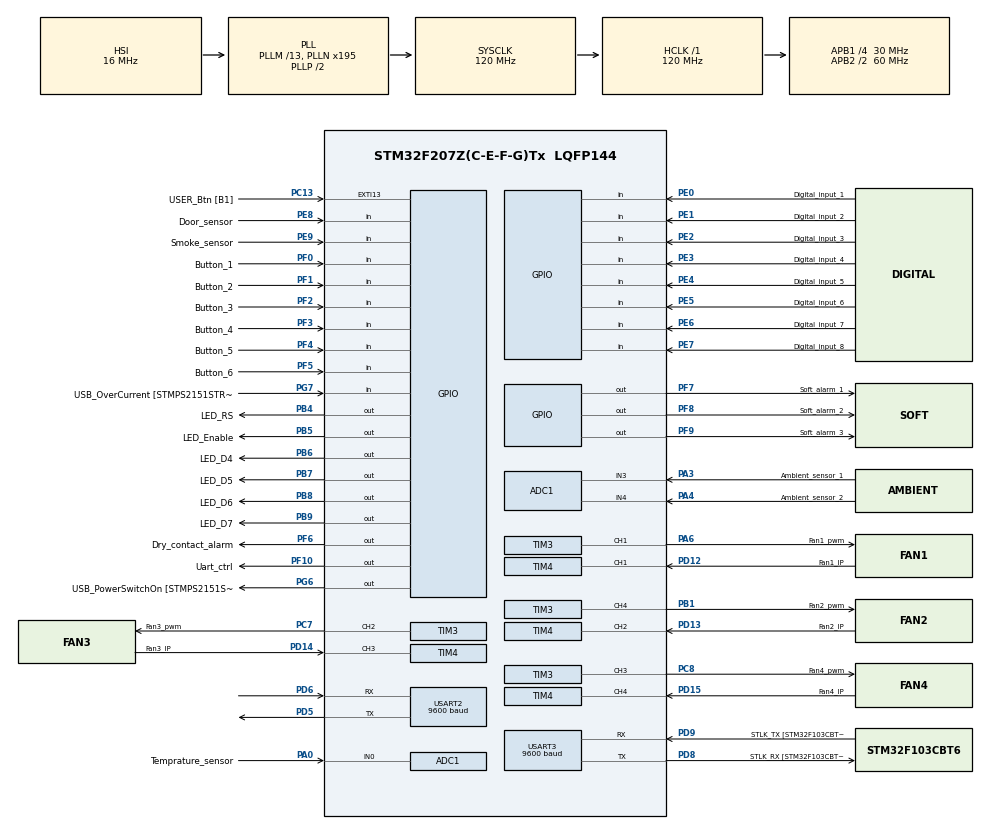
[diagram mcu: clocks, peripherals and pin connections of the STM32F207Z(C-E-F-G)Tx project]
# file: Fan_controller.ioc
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ADC1.Channel-0\#ChannelRegularConversion=ADC_CHANNEL_0
ADC1.Channel-1\#ChannelRegularConversion=ADC_CHANNEL_3
ADC1.Channel-2\#ChannelRegularConversion=ADC_CHANNEL_4
ADC1.ContinuousConvMode=ENABLE
ADC1.NbrOfConversion=3
ADC1.NbrOfConversionFlag=1
ADC1.Rank-0\#ChannelRegularConversion=1
ADC1.Rank-1\#ChannelRegularConversion=2
ADC1.Rank-2\#ChannelRegularConversion=3
ADC1.SamplingTime-0\#ChannelRegularConversion=ADC_SAMPLETIME_480CYCLES
ADC1.SamplingTime-1\#ChannelRegularConversion=ADC_SAMPLETIME_480CYCLES
ADC1.SamplingTime-2\#ChannelRegularConversion=ADC_SAMPLETIME_480CYCLES
ADC1.master=1
Mcu.Family=STM32F2
Mcu.Name=STM32F207Z(C-E-F-G)Tx
Mcu.Package=LQFP144
NVIC.ADC_IRQn=true\:0\:0\:false\:false\:true\:true\:true\:true
NVIC.PriorityGroup=NVIC_PRIORITYGROUP_4
NVIC.TIM3_IRQn=true\:0\:0\:false\:false\:true\:true\:true\:true
NVIC.TIM4_IRQn=true\:0\:0\:false\:false\:true\:true\:true\:true
NVIC.TIM6_DAC_IRQn=true\:0\:0\:false\:false\:true\:true\:true\:true
NVIC.USART2_IRQn=true\:0\:0\:false\:false\:true\:true\:true\:true
NVIC.USART3_IRQn=true\:0\:0\:false\:false\:true\:true\:true\:true
PA0-WKUP.GPIO_Label=Temprature_sensor
PA0-WKUP.Signal=ADCx_IN0
PA1.GPIO_Label=RMII_REF_CLK [LAN8742A-CZ-TR_REFCLK0]
PA1.Signal=ETH_REF_CLK
PA10.GPIO_Label=USB_ID
PA10.Signal=USB_OTG_FS_ID
PA11.GPIO_Label=USB_DM
PA11.Signal=USB_OTG_FS_DM
PA12.GPIO_Label=USB_DP
PA12.Signal=USB_OTG_FS_DP
PA13.GPIO_Label=TMS
PA13.Mode=Serial_Wire
PA13.Signal=SYS_JTMS-SWDIO
PA14.GPIO_Label=TCK
PA14.Mode=Serial_Wire
PA14.Signal=SYS_JTCK-SWCLK
PA2.GPIO_Label=RMII_MDIO [LAN8742A-CZ-TR_MDIO]
PA2.Signal=ETH_MDIO
PA3.GPIO_Label=Ambient_sensor_1
PA3.Signal=ADCx_IN3
PA4.GPIO_Label=Ambient_sensor_2
PA4.Signal=ADCx_IN4
PA6.GPIO_Label=Fan1_pwm
PA6.Signal=S_TIM3_CH1
PA7.GPIO_Label=RMII_CRS_DV [LAN8742A-CZ-TR_CRS_DV]
PA7.Signal=ETH_CRS_DV
PA8.GPIO_Label=USB_SOF [TP1]
PA8.Signal=USB_OTG_FS_SOF
PA9.GPIO_Label=USB_VBUS
PA9.Signal=USB_OTG_FS_VBUS
PB1.GPIO_Label=Fan2_pwm
PB1.Signal=S_TIM3_CH4
PB13.GPIO_Label=RMII_TXD1 [LAN8742A-CZ-TR_TXD1]
PB13.Signal=ETH_TXD1
PB3.GPIO_Label=SWO
PB3.Signal=SYS_JTDO-SWO
PB4.GPIO_Label=LED_RS
PB4.Signal=GPIO_Output
PB5.GPIO_Label=LED_Enable
PB5.Signal=GPIO_Output
PB6.GPIO_Label=LED_D4
PB6.Signal=GPIO_Output
PB7.GPIO_Label=LED_D5
PB7.Signal=GPIO_Output
PB8.GPIO_Label=LED_D6
PB8.Signal=GPIO_Output
PB9.GPIO_Label=LED_D7
PB9.Signal=GPIO_Output
PC1.GPIO_Label=RMII_MDC [LAN8742A-CZ-TR_MDC]
PC1.Signal=ETH_MDC
PC13.GPIO_Label=USER_Btn [B1]
PC13.Signal=GPXTI13
PC14-OSC32_IN.Signal=RCC_OSC32_IN
PC15-OSC32_OUT.Signal=RCC_OSC32_OUT
PC4.GPIO_Label=RMII_RXD0 [LAN8742A-CZ-TR_RXD0]
PC4.Signal=ETH_RXD0
PC5.GPIO_Label=RMII_RXD1 [LAN8742A-CZ-TR_RXD1]
PC5.Signal=ETH_RXD1
PC7.GPIO_Label=Fan3_pwm
PC7.Signal=S_TIM3_CH2
PC8.GPIO_Label=Fan4_pwm
PC8.Signal=S_TIM3_CH3
PD12.GPIO_Label=Fan1_IP
PD12.Signal=S_TIM4_CH1
PD13.GPIO_Label=Fan2_IP
PD13.Signal=S_TIM4_CH2
PD14.GPIO_Label=Fan3_IP
PD14.Signal=S_TIM4_CH3
PD15.GPIO_Label=Fan4_IP
PD15.Signal=S_TIM4_CH4
PD5.Mode=Asynchronous
PD5.Signal=USART2_TX
PD6.Mode=Asynchronous
PD6.Signal=USART2_RX
PD8.GPIO_Label=STLK_RX [STM32F103CBT6_PA2]
PD8.Mode=Asynchronous
PD8.Signal=USART3_TX
PD9.GPIO_Label=STLK_TX [STM32F103CBT6_PA3]
PD9.Mode=Asynchronous
PD9.Signal=USART3_RX
PE0.GPIO_Label=Digital_input_1
PE0.Signal=GPIO_Input
PE1.GPIO_Label=Digital_input_2
PE1.Signal=GPIO_Input
PE2.GPIO_Label=Digital_input_3
PE2.Signal=GPIO_Input
PE3.GPIO_Label=Digital_input_4
PE3.Signal=GPIO_Input
PE4.GPIO_Label=Digital_input_5
PE4.Signal=GPIO_Input
PE5.GPIO_Label=Digital_input_6
PE5.Signal=GPIO_Input
PE6.GPIO_Label=Digital_input_7
PE6.Signal=GPIO_Input
PE7.GPIO_Label=Digital_input_8
PE7.Signal=GPIO_Input
PE8.GPIO_Label=Door_sensor
PE8.Signal=GPIO_Input
PE9.GPIO_Label=Smoke_sensor
PE9.Signal=GPIO_Input
PF0.GPIO_Label=Button_1
PF0.Signal=GPIO_Input
PF1.GPIO_Label=Button_2
PF1.Signal=GPIO_Input
PF10.GPIO_Label=Uart_ctrl
PF10.Signal=GPIO_Output
PF2.GPIO_Label=Button_3
PF2.Signal=GPIO_Input
PF3.GPIO_Label=Button_4
PF3.Signal=GPIO_Input
PF4.GPIO_Label=Button_5
PF4.Signal=GPIO_Input
PF5.GPIO_Label=Button_6
PF5.Signal=GPIO_Input
PF6.GPIO_Label=Dry_contact_alarm
PF6.Signal=GPIO_Output
PF7.GPIO_Label=Soft_alarm_1
PF7.Signal=GPIO_Output
PF8.GPIO_Label=Soft_alarm_2
PF8.Signal=GPIO_Output
PF9.GPIO_Label=Soft_alarm_3
PF9.Signal=GPIO_Output
PG11.GPIO_Label=RMII_TX_EN [LAN8742A-CZ-TR_TXEN]
PG11.Signal=ETH_TX_EN
PG13.GPIO_Label=RMII_TXD0 [LAN8742A-CZ-TR_TXD0]
PG13.Signal=ETH_TXD0
PG6.GPIO_Label=USB_PowerSwitchOn [STMPS2151STR_EN]
PG6.Signal=GPIO_Output
PG7.GPIO_Label=USB_OverCurrent [STMPS2151STR_FAULT]
PG7.Signal=GPIO_Input
PH0-OSC_IN.GPIO_Label=MCO [STM32F103CBT6_PA8]
PH0-OSC_IN.Mode=HSE-External-Oscillator
PH0-OSC_IN.Signal=RCC_OSC_IN
PH1-OSC_OUT.Mode=HSE-External-Oscillator
PH1-OSC_OUT.Signal=RCC_OSC_OUT
ProjectManager.HeapSize=0x200
ProjectManager.StackSize=0x400
ProjectManager.TargetToolchain=STM32CubeIDE
RCC.48MHZClocksFreq_Value=48000000
RCC.AHBFreq_Value=120000000
RCC.APB1CLKDivider=RCC_HCLK_DIV4
RCC.APB1Freq_Value=30000000
RCC.APB1TimFreq_Value=60000000
RCC.APB2CLKDivider=RCC_HCLK_DIV2
RCC.APB2Freq_Value=60000000
RCC.APB2TimFreq_Value=120000000
RCC.CortexFreq_Value=120000000
RCC.HCLKFreq_Value=120000000
RCC.HSE_VALUE=8000000
RCC.HSI_VALUE=16000000
RCC.LSE_VALUE=32768
RCC.PLLM=13
RCC.PLLMUL=RCC_PLL_MUL9
RCC.PLLN=195
RCC.PLLQ=5
RCC.PRESCALERUSB=RCC_USBCLKSOURCE_PLL_DIV1_5
RCC.SYSCLKFreq_VALUE=120000000
RCC.SYSCLKSource=RCC_SYSCLKSOURCE_PLLCLK
RCC.SYSCLKSourceVirtual=RCC_SYSCLKSOURCE_PLLCLK
RCC.USBFreq_Value=48000000
RCC.VCOOutputFreq_Value=240000000
SH.ADCx_IN0.0=ADC1_IN0,IN0
SH.ADCx_IN3.0=ADC1_IN3,IN3
SH.ADCx_IN4.0=ADC1_IN4,IN4
SH.S_TIM3_CH1.0=TIM3_CH1,PWM Generation1 CH1
SH.S_TIM3_CH2.0=TIM3_CH2,PWM Generation2 CH2
SH.S_TIM3_CH3.0=TIM3_CH3,PWM Generation3 CH3
SH.S_TIM3_CH4.0=TIM3_CH4,PWM Generation4 CH4
SH.S_TIM4_CH1.0=TIM4_CH1,Input_Capture1_from_TI1
SH.S_TIM4_CH2.0=TIM4_CH2,Input_Capture2_from_TI2
SH.S_TIM4_CH3.0=TIM4_CH3,Input_Capture3_from_TI3
SH.S_TIM4_CH4.0=TIM4_CH4,Input_Capture4_from_TI4
TIM3.AutoReloadPreload=TIM_AUTORELOAD_PRELOAD_ENABLE
TIM3.Channel-PWM\ Generation1\ CH1=TIM_CHANNEL_1
TIM3.Channel-PWM\ Generation2\ CH2=TIM_CHANNEL_2
TIM3.Channel-PWM\ Generation3\ CH3=TIM_CHANNEL_3
TIM3.Channel-PWM\ Generation4\ CH4=TIM_CHANNEL_4
TIM3.Period=100
TIM3.Prescaler=23
TIM4.Channel-Input_Capture1_from_TI1=TIM_CHANNEL_1
TIM4.Channel-Input_Capture2_from_TI2=TIM_CHANNEL_2
TIM4.Channel-Input_Capture3_from_TI3=TIM_CHANNEL_3
TIM4.Channel-Input_Capture4_from_TI4=TIM_CHANNEL_4
TIM6.AutoReloadPreload=TIM_AUTORELOAD_PRELOAD_ENABLE
TIM6.Period=2000
TIM6.Prescaler=600
USART2.BaudRate=9600
USART2.VirtualMode=VM_ASYNC
USART3.BaudRate=9600
USART3.VirtualMode=VM_ASYNC
VP_TIM3_VS_ClockSourceINT.Mode=Internal
VP_TIM4_VS_ClockSourceINT.Mode=Internal
VP_TIM6_VS_ClockSourceINT.Mode=Enable_Timer
board=NUCLEO-F207ZG

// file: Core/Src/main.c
/* USER CODE BEGIN Header */
/**
  ******************************************************************************
  * @file           : main.c
  * @brief          : Main program body
  ******************************************************************************
  * @attention
  *
  * Copyright (c) 2024 STMicroelectronics.
  * All rights reserved.
  *
  * This software is licensed under terms that can be found in the LICENSE file
  * in the root directory of this software component.
  * If no LICENSE file comes with this software, it is provided AS-IS.
  *
  ******************************************************************************
  */
/* USER CODE END Header */
#include "main.h"
#include "Fan.h"
#include <math.h>

void SystemClock_Config(void);
static void MX_GPIO_Init(void);
static void MX_USART3_UART_Init(void);
static void MX_ADC1_Init(void);
static void MX_TIM3_Init(void);
static void MX_TIM4_Init(void);
static void MX_USART2_UART_Init(void);
static void MX_TIM6_Init(void);
uint16_t Adc_buff[3];

int main(void)
{

  /* MCU Configuration--------------------------------------------------------*/

  /* Reset of all peripherals, Initializes the Flash interface and the Systick. */
  HAL_Init();

  /* Configure the system clock */
  SystemClock_Config();

  /* Initialize all configured peripherals */
  MX_GPIO_Init();
  MX_USART3_UART_Init();
  MX_ADC1_Init();
  MX_TIM3_Init();
  MX_TIM4_Init();
  MX_USART2_UART_Init();
  MX_TIM6_Init();

  /* USER CODE BEGIN 2 */
  HAL_TIM_Base_Start_IT(&htim6);
  HAL_ADC_Start_DMA(&hadc1, (uint32_t *) Adc_buff,3);
  /* USER CODE END 2 */

  /* Infinite loop */
  while (1)
  {

  }
}
void HAL_ADC_ConvCpltCallback(ADC_HandleTypeDef* hadc)
{
	Adc_Complition_flag = 1;
	Set_Fan_speed();
}

void HAL_TIM_PeriodElapsedCallback(TIM_HandleTypeDef *htim)
{
	if (htim->Instance == TIM6)
	{

		Read_sensors();
		Read_ADC_value();
		set_alarm();

	}

}

void Read_ADC_value()
{
	 if(Adc_Complition_flag)
		  {
			  for(uint8_t i=0; i<hadc1.Init.NbrOfConversion; i++)
			  {
				  Temperature_sensor = (uint16_t) Adc_buff[0]; // set temperature value as per sensor o/p in degree celcius
				  Ambient_sensor_1 = (uint16_t) Adc_buff[1];
				  Ambient_sensor_2 = (uint16_t) Adc_buff[2];
				  Adc_Complition_flag = 0;
				  HAL_ADC_Start_DMA(&hadc1, (uint32_t *) Adc_buff,3);

			  }
		  }
}

void Read_sensors()
{
	Door_status 	= (HAL_GPIO_ReadPin(Door_sensor_GPIO_Port, Door_sensor_Pin) == GPIO_PIN_SET) ? 1 : 0;
	Smoke_sensor 	= (HAL_GPIO_ReadPin(Smoke_sensor_GPIO_Port, Smoke_sensor_Pin) == GPIO_PIN_SET) ? 1 : 0;
	Digital_input_1 = (HAL_GPIO_ReadPin(Digital_input_1_GPIO_Port, Digital_input_1_Pin) == GPIO_PIN_SET) ? 1 : 0;
	Digital_input_2 = (HAL_GPIO_ReadPin(Digital_input_2_GPIO_Port, Digital_input_2_Pin) == GPIO_PIN_SET) ? 1 : 0;
	Digital_input_3 = (HAL_GPIO_ReadPin(Digital_input_3_GPIO_Port, Digital_input_3_Pin) == GPIO_PIN_SET) ? 1 : 0;
	Digital_input_4 = (HAL_GPIO_ReadPin(Digital_input_4_GPIO_Port, Digital_input_4_Pin) == GPIO_PIN_SET) ? 1 : 0;
	Digital_input_5 = (HAL_GPIO_ReadPin(Digital_input_5_GPIO_Port, Digital_input_5_Pin) == GPIO_PIN_SET) ? 1 : 0;
	Digital_input_6 = (HAL_GPIO_ReadPin(Digital_input_6_GPIO_Port, Digital_input_6_Pin) == GPIO_PIN_SET) ? 1 : 0;
	Digital_input_7 = (HAL_GPIO_ReadPin(Digital_input_7_GPIO_Port, Digital_input_7_Pin) == GPIO_PIN_SET) ? 1 : 0;
	Digital_input_8 = (HAL_GPIO_ReadPin(Digital_input_8_GPIO_Port, Digital_input_8_Pin) == GPIO_PIN_SET) ? 1 : 0;
}

void Set_Fan_speed()
{
	 float deltaT = fabs(Temperature_sensor - Ambient_sensor_1); // Make delta positive
	 uint8_t duty_cycle = 0;

	 	 if (Temperature_sensor < 30)
	 	 {
	         duty_cycle = 0; // Off
	     }
	     else if (Temperature_sensor < 35)
	     {
	         duty_cycle = 20;
	     }
	     else if (Temperature_sensor < 40)
	     {
	         if (deltaT <= 2.5)
	         {
	             duty_cycle = 20;         // Delta T <= 2.5
	         }
	         else if (deltaT <= 5.0)
	         {
	             duty_cycle = 30;         // 2.5 < Delta T <= 5.0
	         }
	         else if (deltaT <= 7.5)
	         {
	             duty_cycle = 40;         // 5.0 < Delta T <= 7.5
	         }
	         else if (deltaT <= 10)
	         {
	             duty_cycle = 50;         // 7.5 < Delta T <= 10
	         }
	         else if (deltaT <= 12.5)
	         {
	             duty_cycle = 60;         // 10 < Delta T <= 12.5
	         }
	         else
	         {
	             duty_cycle = 80;         // Delta T > 12.5
	         }
	     }
	     else if (Temperature_sensor < 45)
	     {
	         if (deltaT <= 2.5)
	         {
	             duty_cycle = 30;         // Delta T <= 2.5
	         }
	         else if (deltaT <= 5.0)
	         {
	             duty_cycle = 40;         // 2.5 < Delta T <= 5.0
	         }
	         else if (deltaT <= 7.5)
	         {
	             duty_cycle = 70;         // 5.0 < Delta T <= 7.5
	         }
	         else if (deltaT <= 10)
	         {
	             duty_cycle = 80;         // 7.5 < Delta T <= 10
	         }
	         else if (deltaT <= 12.5)
	         {
	             duty_cycle = 90;         // 10 < Delta T <= 12.5
	         }
	         else
	         {
	             duty_cycle = 100;        // Delta T > 12.5
	         }
	     }
	     else if (Temperature_sensor < 50)
	     {
	         if (deltaT <= 2.5)

	         {
	             duty_cycle = 50;         // Delta T <= 2.5
	         }
	         else if (deltaT <= 5.0)
	         {
	             duty_cycle = 80;         // 2.5 < Delta T <= 5.0
	         }
	         else
	         {
	             duty_cycle = 100;        // Delta T > 5.0
	         }
	     }
	     else
	     {
	         if (deltaT < 2.5)
	         {
	             duty_cycle = 70;         // Delta T < 2.5
	         }
	         else
	         {
	             duty_cycle = 100;        // Delta T >= 2.5
	         }
	     }
	 	__HAL_TIM_SET_COMPARE(&htim3, TIM_CHANNEL_1, duty_cycle);
	 	__HAL_TIM_SET_COMPARE(&htim3, TIM_CHANNEL_2, duty_cycle);
	 	__HAL_TIM_SET_COMPARE(&htim3, TIM_CHANNEL_3, duty_cycle);
	 	__HAL_TIM_SET_COMPARE(&htim3, TIM_CHANNEL_4, duty_cycle);
}

void SystemClock_Config(void)
{
  RCC_OscInitTypeDef RCC_OscInitStruct = {0};
  RCC_ClkInitTypeDef RCC_ClkInitStruct = {0};

  /** Initializes the RCC Oscillators according to the specified parameters
  * in the RCC_OscInitTypeDef structure.
  */
  RCC_OscInitStruct.OscillatorType = RCC_OSCILLATORTYPE_HSI;
  RCC_OscInitStruct.HSIState = RCC_HSI_ON;
  RCC_OscInitStruct.HSICalibrationValue = RCC_HSICALIBRATION_DEFAULT;
  RCC_OscInitStruct.PLL.PLLState = RCC_PLL_ON;
  RCC_OscInitStruct.PLL.PLLSource = RCC_PLLSOURCE_HSI;
  RCC_OscInitStruct.PLL.PLLM = 13;
  RCC_OscInitStruct.PLL.PLLN = 195;
  RCC_OscInitStruct.PLL.PLLP = RCC_PLLP_DIV2;
  RCC_OscInitStruct.PLL.PLLQ = 5;
  if (HAL_RCC_OscConfig(&RCC_OscInitStruct) != HAL_OK)
  {
    Error_Handler();
  }

  /** Initializes the CPU, AHB and APB buses clocks
  */
  RCC_ClkInitStruct.ClockType = RCC_CLOCKTYPE_HCLK|RCC_CLOCKTYPE_SYSCLK
                              |RCC_CLOCKTYPE_PCLK1|RCC_CLOCKTYPE_PCLK2;
  RCC_ClkInitStruct.SYSCLKSource = RCC_SYSCLKSOURCE_PLLCLK;
  RCC_ClkInitStruct.AHBCLKDivider = RCC_SYSCLK_DIV1;
  RCC_ClkInitStruct.APB1CLKDivider = RCC_HCLK_DIV4;
  RCC_ClkInitStruct.APB2CLKDivider = RCC_HCLK_DIV2;

  if (HAL_RCC_ClockConfig(&RCC_ClkInitStruct, FLASH_LATENCY_3) != HAL_OK)
  {
    Error_Handler();
  }
}

static void MX_ADC1_Init(void)
{

  ADC_ChannelConfTypeDef sConfig = {0};

  /** Configure the global features of the ADC (Clock, Resolution, Data Alignment and number of conversion)
  */
  hadc1.Instance = ADC1;
  hadc1.Init.ClockPrescaler = ADC_CLOCK_SYNC_PCLK_DIV2;
  hadc1.Init.Resolution = ADC_RESOLUTION_12B;
  hadc1.Init.ScanConvMode = ENABLE;
  hadc1.Init.ContinuousConvMode = ENABLE;
  hadc1.Init.DiscontinuousConvMode = DISABLE;
  hadc1.Init.ExternalTrigConvEdge = ADC_EXTERNALTRIGCONVEDGE_NONE;
  hadc1.Init.ExternalTrigConv = ADC_SOFTWARE_START;
  hadc1.Init.DataAlign = ADC_DATAALIGN_RIGHT;
  hadc1.Init.NbrOfConversion = 3;
  hadc1.Init.DMAContinuousRequests = DISABLE;
  hadc1.Init.EOCSelection = ADC_EOC_SINGLE_CONV;
  if (HAL_ADC_Init(&hadc1) != HAL_OK)
  {
    Error_Handler();
  }

  /** Configure for the selected ADC regular channel its corresponding rank in the sequencer and its sample time.
  */
  sConfig.Channel = ADC_CHANNEL_0;
  sConfig.Rank = 1;
  sConfig.SamplingTime = ADC_SAMPLETIME_480CYCLES;
  if (HAL_ADC_ConfigChannel(&hadc1, &sConfig) != HAL_OK)
  {
    Error_Handler();
  }

  /** Configure for the selected ADC regular channel its corresponding rank in the sequencer and its sample time.
  */
  sConfig.Channel = ADC_CHANNEL_3;
  sConfig.Rank = 2;
  if (HAL_ADC_ConfigChannel(&hadc1, &sConfig) != HAL_OK)
  {
    Error_Handler();
  }

  /** Configure for the selected ADC regular channel its corresponding rank in the sequencer and its sample time.
  */
  sConfig.Channel = ADC_CHANNEL_4;
  sConfig.Rank = 3;
  if (HAL_ADC_ConfigChannel(&hadc1, &sConfig) != HAL_OK)
  {
    Error_Handler();
  }

}

static void MX_TIM3_Init(void)
{

  TIM_ClockConfigTypeDef sClockSourceConfig = {0};
  TIM_MasterConfigTypeDef sMasterConfig = {0};
  TIM_OC_InitTypeDef sConfigOC = {0};

  htim3.Instance = TIM3;
  htim3.Init.Prescaler = 23;
  htim3.Init.CounterMode = TIM_COUNTERMODE_UP;
  htim3.Init.Period = 100;
  htim3.Init.ClockDivision = TIM_CLOCKDIVISION_DIV1;
  htim3.Init.AutoReloadPreload = TIM_AUTORELOAD_PRELOAD_ENABLE;
  if (HAL_TIM_Base_Init(&htim3) != HAL_OK)
  {
    Error_Handler();
  }
  sClockSourceConfig.ClockSource = TIM_CLOCKSOURCE_INTERNAL;
  if (HAL_TIM_ConfigClockSource(&htim3, &sClockSourceConfig) != HAL_OK)
  {
    Error_Handler();
  }
  if (HAL_TIM_PWM_Init(&htim3) != HAL_OK)
  {
    Error_Handler();
  }
  sMasterConfig.MasterOutputTrigger = TIM_TRGO_RESET;
  sMasterConfig.MasterSlaveMode = TIM_MASTERSLAVEMODE_DISABLE;
  if (HAL_TIMEx_MasterConfigSynchronization(&htim3, &sMasterConfig) != HAL_OK)
  {
    Error_Handler();
  }
  sConfigOC.OCMode = TIM_OCMODE_PWM1;
  sConfigOC.Pulse = 0;
  sConfigOC.OCPolarity = TIM_OCPOLARITY_HIGH;
  sConfigOC.OCFastMode = TIM_OCFAST_DISABLE;
  if (HAL_TIM_PWM_ConfigChannel(&htim3, &sConfigOC, TIM_CHANNEL_1) != HAL_OK)
  {
    Error_Handler();
  }
  if (HAL_TIM_PWM_ConfigChannel(&htim3, &sConfigOC, TIM_CHANNEL_2) != HAL_OK)
  {
    Error_Handler();
  }
  if (HAL_TIM_PWM_ConfigChannel(&htim3, &sConfigOC, TIM_CHANNEL_3) != HAL_OK)
  {
    Error_Handler();
  }
  if (HAL_TIM_PWM_ConfigChannel(&htim3, &sConfigOC, TIM_CHANNEL_4) != HAL_OK)
  {
    Error_Handler();
  }
  HAL_TIM_MspPostInit(&htim3);

}

static void MX_TIM4_Init(void)
{

  TIM_ClockConfigTypeDef sClockSourceConfig = {0};
  TIM_MasterConfigTypeDef sMasterConfig = {0};
  TIM_IC_InitTypeDef sConfigIC = {0};

  htim4.Instance = TIM4;
  htim4.Init.Prescaler = 0;
  htim4.Init.CounterMode = TIM_COUNTERMODE_UP;
  htim4.Init.Period = 65535;
  htim4.Init.ClockDivision = TIM_CLOCKDIVISION_DIV1;
  htim4.Init.AutoReloadPreload = TIM_AUTORELOAD_PRELOAD_DISABLE;
  if (HAL_TIM_Base_Init(&htim4) != HAL_OK)
  {
    Error_Handler();
  }
  sClockSourceConfig.ClockSource = TIM_CLOCKSOURCE_INTERNAL;
  if (HAL_TIM_ConfigClockSource(&htim4, &sClockSourceConfig) != HAL_OK)
  {
    Error_Handler();
  }
  if (HAL_TIM_IC_Init(&htim4) != HAL_OK)
  {
    Error_Handler();
  }
  sMasterConfig.MasterOutputTrigger = TIM_TRGO_RESET;
  sMasterConfig.MasterSlaveMode = TIM_MASTERSLAVEMODE_DISABLE;
  if (HAL_TIMEx_MasterConfigSynchronization(&htim4, &sMasterConfig) != HAL_OK)
  {
    Error_Handler();
  }
  sConfigIC.ICPolarity = TIM_INPUTCHANNELPOLARITY_RISING;
  sConfigIC.ICSelection = TIM_ICSELECTION_DIRECTTI;
  sConfigIC.ICPrescaler = TIM_ICPSC_DIV1;
  sConfigIC.ICFilter = 0;
  if (HAL_TIM_IC_ConfigChannel(&htim4, &sConfigIC, TIM_CHANNEL_1) != HAL_OK)
  {
    Error_Handler();
  }
  if (HAL_TIM_IC_ConfigChannel(&htim4, &sConfigIC, TIM_CHANNEL_2) != HAL_OK)
  {
    Error_Handler();
  }
  if (HAL_TIM_IC_ConfigChannel(&htim4, &sConfigIC, TIM_CHANNEL_3) != HAL_OK)
  {
    Error_Handler();
  }
  if (HAL_TIM_IC_ConfigChannel(&htim4, &sConfigIC, TIM_CHANNEL_4) != HAL_OK)
  {
    Error_Handler();
  }

}

static void MX_TIM6_Init(void)
{

  TIM_MasterConfigTypeDef sMasterConfig = {0};

  htim6.Instance = TIM6;
  htim6.Init.Prescaler = 600;
  htim6.Init.CounterMode = TIM_COUNTERMODE_UP;
  htim6.Init.Period = 2000;
  htim6.Init.AutoReloadPreload = TIM_AUTORELOAD_PRELOAD_ENABLE;
  if (HAL_TIM_Base_Init(&htim6) != HAL_OK)
  {
    Error_Handler();
  }
  sMasterConfig.MasterOutputTrigger = TIM_TRGO_RESET;
  sMasterConfig.MasterSlaveMode = TIM_MASTERSLAVEMODE_DISABLE;
  if (HAL_TIMEx_MasterConfigSynchronization(&htim6, &sMasterConfig) != HAL_OK)
  {
    Error_Handler();
  }

}

static void MX_USART2_UART_Init(void)
{

  huart2.Instance = USART2;
  huart2.Init.BaudRate = 9600;
  huart2.Init.WordLength = UART_WORDLENGTH_8B;
  huart2.Init.StopBits = UART_STOPBITS_1;
  huart2.Init.Parity = UART_PARITY_NONE;
  huart2.Init.Mode = UART_MODE_TX_RX;
  huart2.Init.HwFlowCtl = UART_HWCONTROL_NONE;
  huart2.Init.OverSampling = UART_OVERSAMPLING_16;
  if (HAL_UART_Init(&huart2) != HAL_OK)
  {
    Error_Handler();
  }

}

static void MX_USART3_UART_Init(void)
{

  huart3.Instance = USART3;
  huart3.Init.BaudRate = 9600;
  huart3.Init.WordLength = UART_WORDLENGTH_8B;
  huart3.Init.StopBits = UART_STOPBITS_1;
  huart3.Init.Parity = UART_PARITY_NONE;
  huart3.Init.Mode = UART_MODE_TX_RX;
  huart3.Init.HwFlowCtl = UART_HWCONTROL_NONE;
  huart3.Init.OverSampling = UART_OVERSAMPLING_16;
  if (HAL_UART_Init(&huart3) != HAL_OK)
  {
    Error_Handler();
  }

}

static void MX_GPIO_Init(void)
{
  GPIO_InitTypeDef GPIO_InitStruct = {0};

  /* GPIO Ports Clock Enable */
  __HAL_RCC_GPIOE_CLK_ENABLE();
  __HAL_RCC_GPIOC_CLK_ENABLE();
  __HAL_RCC_GPIOF_CLK_ENABLE();
  __HAL_RCC_GPIOH_CLK_ENABLE();
  __HAL_RCC_GPIOA_CLK_ENABLE();
  __HAL_RCC_GPIOB_CLK_ENABLE();
  __HAL_RCC_GPIOD_CLK_ENABLE();
  __HAL_RCC_GPIOG_CLK_ENABLE();

  /*Configure GPIO pin Output Level */
  HAL_GPIO_WritePin(GPIOF, Dry_contact_alarm_Pin|Soft_alarm_1_Pin|Soft_alarm_2_Pin|Soft_alarm_3_Pin
                          |Uart_ctrl_Pin, GPIO_PIN_RESET);

  /*Configure GPIO pin Output Level */
  HAL_GPIO_WritePin(USB_PowerSwitchOn_GPIO_Port, USB_PowerSwitchOn_Pin, GPIO_PIN_RESET);

  /*Configure GPIO pin Output Level */
  HAL_GPIO_WritePin(GPIOB, LED_RS_Pin|LED_Enable_Pin|LED_D4_Pin|LED_D5_Pin
                          |LED_D6_Pin|LED_D7_Pin, GPIO_PIN_RESET);

  /*Configure GPIO pins : Digital_input_3_Pin Digital_input_4_Pin Digital_input_5_Pin Digital_input_6_Pin
                           Digital_input_7_Pin Digital_input_8_Pin Door_sensor_Pin Smoke_sensor_Pin
                           Digital_input_1_Pin Digital_input_2_Pin */
  GPIO_InitStruct.Pin = Digital_input_3_Pin|Digital_input_4_Pin|Digital_input_5_Pin|Digital_input_6_Pin
                          |Digital_input_7_Pin|Digital_input_8_Pin|Door_sensor_Pin|Smoke_sensor_Pin
                          |Digital_input_1_Pin|Digital_input_2_Pin;
  GPIO_InitStruct.Mode = GPIO_MODE_INPUT;
  GPIO_InitStruct.Pull = GPIO_NOPULL;
  HAL_GPIO_Init(GPIOE, &GPIO_InitStruct);

  /*Configure GPIO pin : USER_Btn_Pin */
  GPIO_InitStruct.Pin = USER_Btn_Pin;
  GPIO_InitStruct.Mode = GPIO_MODE_IT_RISING;
  GPIO_InitStruct.Pull = GPIO_NOPULL;
  HAL_GPIO_Init(USER_Btn_GPIO_Port, &GPIO_InitStruct);

  /*Configure GPIO pins : Button_1_Pin Button_2_Pin Button_3_Pin Button_4_Pin
                           Button_5_Pin Button_6_Pin */
  GPIO_InitStruct.Pin = Button_1_Pin|Button_2_Pin|Button_3_Pin|Button_4_Pin
                          |Button_5_Pin|Button_6_Pin;
  GPIO_InitStruct.Mode = GPIO_MODE_INPUT;
  GPIO_InitStruct.Pull = GPIO_NOPULL;
  HAL_GPIO_Init(GPIOF, &GPIO_InitStruct);

  /*Configure GPIO pins : Dry_contact_alarm_Pin Soft_alarm_1_Pin Soft_alarm_2_Pin Soft_alarm_3_Pin
                           Uart_ctrl_Pin */
  GPIO_InitStruct.Pin = Dry_contact_alarm_Pin|Soft_alarm_1_Pin|Soft_alarm_2_Pin|Soft_alarm_3_Pin
                          |Uart_ctrl_Pin;
  GPIO_InitStruct.Mode = GPIO_MODE_OUTPUT_PP;
  GPIO_InitStruct.Pull = GPIO_NOPULL;
  GPIO_InitStruct.Speed = GPIO_SPEED_FREQ_LOW;
  HAL_GPIO_Init(GPIOF, &GPIO_InitStruct);

  /*Configure GPIO pins : RMII_MDC_Pin RMII_RXD0_Pin RMII_RXD1_Pin */
  GPIO_InitStruct.Pin = RMII_MDC_Pin|RMII_RXD0_Pin|RMII_RXD1_Pin;
  GPIO_InitStruct.Mode = GPIO_MODE_AF_PP;
  GPIO_InitStruct.Pull = GPIO_NOPULL;
  GPIO_InitStruct.Speed = GPIO_SPEED_FREQ_VERY_HIGH;
  GPIO_InitStruct.Alternate = GPIO_AF11_ETH;
  HAL_GPIO_Init(GPIOC, &GPIO_InitStruct);

  /*Configure GPIO pins : RMII_REF_CLK_Pin RMII_MDIO_Pin RMII_CRS_DV_Pin */
  GPIO_InitStruct.Pin = RMII_REF_CLK_Pin|RMII_MDIO_Pin|RMII_CRS_DV_Pin;
  GPIO_InitStruct.Mode = GPIO_MODE_AF_PP;
  GPIO_InitStruct.Pull = GPIO_NOPULL;
  GPIO_InitStruct.Speed = GPIO_SPEED_FREQ_VERY_HIGH;
  GPIO_InitStruct.Alternate = GPIO_AF11_ETH;
  HAL_GPIO_Init(GPIOA, &GPIO_InitStruct);

  /*Configure GPIO pin : RMII_TXD1_Pin */
  GPIO_InitStruct.Pin = RMII_TXD1_Pin;
  GPIO_InitStruct.Mode = GPIO_MODE_AF_PP;
  GPIO_InitStruct.Pull = GPIO_NOPULL;
  GPIO_InitStruct.Speed = GPIO_SPEED_FREQ_VERY_HIGH;
  GPIO_InitStruct.Alternate = GPIO_AF11_ETH;
  HAL_GPIO_Init(RMII_TXD1_GPIO_Port, &GPIO_InitStruct);

  /*Configure GPIO pin : USB_PowerSwitchOn_Pin */
  GPIO_InitStruct.Pin = USB_PowerSwitchOn_Pin;
  GPIO_InitStruct.Mode = GPIO_MODE_OUTPUT_PP;
  GPIO_InitStruct.Pull = GPIO_NOPULL;
  GPIO_InitStruct.Speed = GPIO_SPEED_FREQ_LOW;
  HAL_GPIO_Init(USB_PowerSwitchOn_GPIO_Port, &GPIO_InitStruct);

  /*Configure GPIO pin : USB_OverCurrent_Pin */
  GPIO_InitStruct.Pin = USB_OverCurrent_Pin;
  GPIO_InitStruct.Mode = GPIO_MODE_INPUT;
  GPIO_InitStruct.Pull = GPIO_NOPULL;
  HAL_GPIO_Init(USB_OverCurrent_GPIO_Port, &GPIO_InitStruct);

  /*Configure GPIO pins : USB_SOF_Pin USB_ID_Pin USB_DM_Pin USB_DP_Pin */
  GPIO_InitStruct.Pin = USB_SOF_Pin|USB_ID_Pin|USB_DM_Pin|USB_DP_Pin;
  GPIO_InitStruct.Mode = GPIO_MODE_AF_PP;
  GPIO_InitStruct.Pull = GPIO_NOPULL;
  GPIO_InitStruct.Speed = GPIO_SPEED_FREQ_VERY_HIGH;
  GPIO_InitStruct.Alternate = GPIO_AF10_OTG_FS;
  HAL_GPIO_Init(GPIOA, &GPIO_InitStruct);

  /*Configure GPIO pin : USB_VBUS_Pin */
  GPIO_InitStruct.Pin = USB_VBUS_Pin;
  GPIO_InitStruct.Mode = GPIO_MODE_INPUT;
  GPIO_InitStruct.Pull = GPIO_NOPULL;
  HAL_GPIO_Init(USB_VBUS_GPIO_Port, &GPIO_InitStruct);

  /*Configure GPIO pins : RMII_TX_EN_Pin RMII_TXD0_Pin */
  GPIO_InitStruct.Pin = RMII_TX_EN_Pin|RMII_TXD0_Pin;
  GPIO_InitStruct.Mode = GPIO_MODE_AF_PP;
  GPIO_InitStruct.Pull = GPIO_NOPULL;
  GPIO_InitStruct.Speed = GPIO_SPEED_FREQ_VERY_HIGH;
  GPIO_InitStruct.Alternate = GPIO_AF11_ETH;
  HAL_GPIO_Init(GPIOG, &GPIO_InitStruct);

  /*Configure GPIO pins : LED_RS_Pin LED_Enable_Pin LED_D4_Pin LED_D5_Pin
                           LED_D6_Pin LED_D7_Pin */
  GPIO_InitStruct.Pin = LED_RS_Pin|LED_Enable_Pin|LED_D4_Pin|LED_D5_Pin
                          |LED_D6_Pin|LED_D7_Pin;
  GPIO_InitStruct.Mode = GPIO_MODE_OUTPUT_PP;
  GPIO_InitStruct.Pull = GPIO_NOPULL;
  GPIO_InitStruct.Speed = GPIO_SPEED_FREQ_LOW;
  HAL_GPIO_Init(GPIOB, &GPIO_InitStruct);

}

void Error_Handler(void)
{
  __disable_irq();
  while (1)
  {
  }
}
